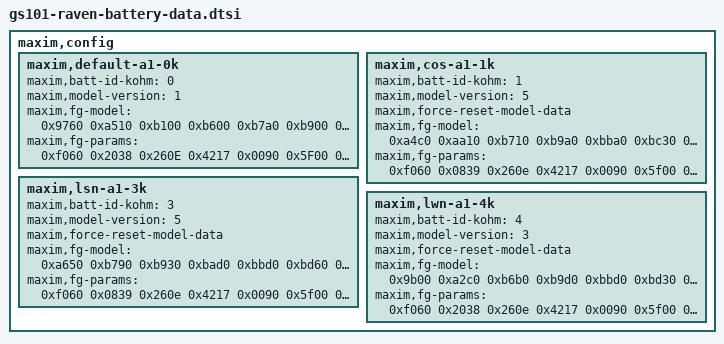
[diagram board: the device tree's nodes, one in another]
// SPDX-License-Identifier: GPL-2.0-only
/*
 * Battery device tree entries
 *
 * Copyright 2020 Google LLC
 *
 */

/* R4_p1_gen.ini, 2021-01-21, b/174787673, generic model */
maxim,config {

	/* R4_p1_gen.ini, 2021-01-21, b/174787673, generic model */
	maxim,default-a1-0k {
		maxim,batt-id-kohm = <0>;
		maxim,model-version = <1>;
		maxim,fg-model = /bits/ 16 <
			0x9760 0xa510 0xb100 0xb600 0xb7a0 0xb900 0xba70 0xbc70
			0xbde0 0xbfc0 0xc250 0xc510 0xc990 0xcea0 0xd040 0xd750
			0x0060 0x0120 0x0200 0x0710 0x0e80 0x0df0 0x1430 0x1bd0
			0x1520 0x0d70 0x0950 0x08e0 0x0800 0x0780 0x06b0 0x01e0
			0x0100 0x0100 0x0100 0x0100 0x0100 0x0100 0x0100 0x0100
			0x0100 0x0100 0x0100 0x0100 0x0100 0x0100 0x0100 0x0100
		>;
		maxim,fg-params = /bits/ 16 <
			/* 0x0036 */	0xf060	/* IAvgEmpty */
			/* 0x002a */	0x2038	/* RelaxCFG */
			/* 0x0028 */	0x260E	/* LearnCFG */
			/* 0x001D */	0x4217	/* Config */
			/* 0x00BB */	0x0090	/* Config2 */
			/* 0x0013 */	0x5F00	/* FullSOCthr */
			/* 0x0035 */	0x0994	/* FullCAPRep */
			/* 0x0018 */	0x0994	/* DesignCap */
			/* 0x0046 */	0x0c80	/* dPacc */
			/* 0x0045 */	0x0099	/* dQacc */
			/* 0x0023 */	0x0994	/* FullCAPNom */
			/* 0x003A */	0xA561	/* V_empty */
			/* 0x0012 */	0x1100	/* QResidual00 */
			/* 0x0022 */	0x0800	/* QResidual10 */
			/* 0x0032 */	0x0301	/* QResidual20 */
			/* 0x0042 */	0x0302	/* QResidual30 */
			/* 0x0038 */	0x0700	/* RCOMP0 */
			/* 0x0039 */	0x223E	/* TempCo */
			/* 0x001E */	0x0310	/* ICHGTerm */
			/* 0x002C */	0xED51	/* TGain */
			/* 0x002D */	0x1EBA	/* TOff */
			/* 0x00B9 */	0x0014	/* Curve */
			/* 0x002B */	0x3870	/* MiscCFG */
			/* 0x0004 */	0x0000	/* AtRate */
			/* 0x0049 */	0x2241	/* convgcfg */
			/* 0x0029 */	0xc623	/* FilterCFG */
			/* 0x003c */	0x2D00	/* TaskPeriod */
		>;
	};

	/* ATL: 1_ATL_2937_2_011421_3.3V_RC2_V03.txt, 2021-11-18, b/205853069 */
	maxim,cos-a1-1k {
		maxim,batt-id-kohm = <1>;
		maxim,model-version = <5>;
		maxim,force-reset-model-data;
		maxim,fg-model = /bits/ 16 <
			0xa4c0 0xaa10 0xb710 0xb9a0 0xbba0 0xbc30 0xbd20 0xbeb0
			0xc030 0xc2e0 0xc560 0xc980 0xcbf0 0xcf10 0xd600 0xdc00
			0x02f0 0x0140 0x0a50 0x0df0 0x13a0 0x0d80 0x1af0 0x1300
			0x0d10 0x07a0 0x0810 0x07c0 0x0780 0x0690 0x0730 0x0730
			0x0200 0x0200 0x0200 0x0200 0x0200 0x0200 0x0200 0x0200
			0x0200 0x0200 0x0200 0x0200 0x0200 0x0200 0x0200 0x0200
		>;
		maxim,fg-params = /bits/ 16 <
			/* 0x0036 */	0xf060	/* IAvgEmpty */
			/* 0x002a */	0x0839	/* RelaxCFG */
			/* 0x0028 */	0x260e	/* LearnCFG */
			/* 0x001D */	0x4217	/* Config */
			/* 0x00BB */	0x0090	/* Config2 */
			/* 0x0013 */	0x5f00	/* FullSOCthr */
			/* 0x0035 */	0x09d6	/* FullCAPRep */
			/* 0x0018 */	0x09d6	/* DesignCap */
			/* 0x0046 */	0x3200	/* dPacc */
			/* 0x0045 */	0x0275	/* dQacc */
			/* 0x0023 */	0x09d6	/* FullCAPNom */
			/* 0x003A */	0xa561	/* V_empty */
			/* 0x0012 */	0x3100	/* QResidual00 */
			/* 0x0022 */	0x1580	/* QResidual10 */
			/* 0x0032 */	0x0800	/* QResidual20 */
			/* 0x0042 */	0x0780	/* QResidual30 */
			/* 0x0038 */	0x0860	/* RCOMP0 */
			/* 0x0039 */	0x0d02	/* TempCo */
			/* 0x001E */	0x0620	/* ICHGTerm */
			/* 0x002C */	0xED51	/* TGain */
			/* 0x002D */	0x1EBA	/* TOff */
			/* 0x00B9 */	0x0014	/* Curve */
			/* 0x002B */	0x3870	/* MiscCFG */
			/* 0x0004 */	0x1900	/* AtRate */
			/* 0x0049 */	0x2241	/* convgcfg */
			/* 0x0029 */	0xc623	/* FilterCFG */
			/* 0x003c */	0x2D00	/* TaskPeriod */
		>;
	};

	/* LSN: 3_LSN_2992_2_040921_3.3_RC2_V03.txt, 2021-11-18, b/205853069 */
	maxim,lsn-a1-3k {
		maxim,batt-id-kohm = <3>;
		maxim,model-version = <5>;
		maxim,force-reset-model-data;
		maxim,fg-model = /bits/ 16 <
			0xa650 0xb790 0xb930 0xbad0 0xbbd0 0xbd60 0xbe80 0xc090
			0xc320 0xc590 0xc890 0xcbf0 0xcdf0 0xd5f0 0xd8b0 0xdd10
			0x01f0 0x0a00 0x0d00 0x1300 0x1350 0x17a0 0x1180 0x0ce0
			0x08c0 0x0750 0x06f0 0x0af0 0x05e0 0x08e0 0x0580 0x0580
			0x0200 0x0200 0x0200 0x0200 0x0200 0x0200 0x0200 0x0200
			0x0200 0x0200 0x0200 0x0200 0x0200 0x0200 0x0200 0x0200
		>;
		maxim,fg-params = /bits/ 16 <
			/* 0x0036 */	0xf060	/* IAvgEmpty */
			/* 0x002a */	0x0839	/* RelaxCFG */
			/* 0x0028 */	0x260e	/* LearnCFG */
			/* 0x001D */	0x4217	/* Config */
			/* 0x00BB */	0x0090	/* Config2 */
			/* 0x0013 */	0x5f00	/* FullSOCthr */
			/* 0x0035 */	0x0A2A	/* FullCAPRep */
			/* 0x0018 */	0x0A2A	/* DesignCap */
			/* 0x0046 */	0x3200	/* dPacc */
			/* 0x0045 */	0x028A	/* dQacc */
			/* 0x0023 */	0x0A2A	/* FullCAPNom */
			/* 0x003A */	0xa561	/* V_empty */
			/* 0x0012 */	0x3180	/* QResidual00 */
			/* 0x0022 */	0x1580	/* QResidual10 */
			/* 0x0032 */	0x0780	/* QResidual20 */
			/* 0x0042 */	0x0580	/* QResidual30 */
			/* 0x0038 */	0x06E0	/* RCOMP0 */
			/* 0x0039 */	0x0a02	/* TempCo */
			/* 0x001E */	0x0620	/* ICHGTerm */
			/* 0x002C */	0xED51	/* TGain */
			/* 0x002D */	0x1EBA	/* TOff */
			/* 0x00B9 */	0x0014	/* Curve */
			/* 0x002B */	0x3870	/* MiscCFG */
			/* 0x0004 */	0x1900	/* AtRate */
			/* 0x0049 */	0x2241	/* convgcfg */
			/* 0x0029 */	0xc623	/* FilterCFG */
			/* 0x003c */	0x2D00	/* TaskPeriod */
		>;
	};

	/* LWN: 4_LWN_011521_RC2, 2021-03-18, b/183051702, characterized INI */
	maxim,lwn-a1-4k {
		maxim,batt-id-kohm = <4>;
		maxim,model-version = <3>;
		maxim,force-reset-model-data;
		maxim,fg-model = /bits/ 16 <
			0x9b00 0xa2c0 0xb6b0 0xb9d0 0xbbd0 0xbd30 0xbe00 0xbf00
			0xc050 0xc280 0xc390 0xc910 0xce50 0xd150 0xd520 0xdbb0
			0x0050 0x00e0 0x0d10 0x1050 0x15b0 0x1920 0x1710 0x1260
			0x0ca0 0x07a0 0x07d0 0x0750 0x0790 0x05f0 0x06a0 0x06a0
			0x0200 0x0200 0x0200 0x0200 0x0200 0x0200 0x0200 0x0200
			0x0200 0x0200 0x0200 0x0200 0x0200 0x0200 0x0200 0x0200
		>;
		maxim,fg-params = /bits/ 16 <
			/* 0x0036 */	0xf060	/* IAvgEmpty */
			/* 0x002a */	0x2038	/* RelaxCFG */
			/* 0x0028 */	0x260e	/* LearnCFG */
			/* 0x001D */	0x4217	/* Config */
			/* 0x00BB */	0x0090	/* Config2 */
			/* 0x0013 */	0x5f00	/* FullSOCthr */
			/* 0x0035 */	0x09ee	/* FullCAPRep */
			/* 0x0018 */	0x09ee	/* DesignCap */
			/* 0x0046 */	0x0C80	/* dPacc */
			/* 0x0045 */	0x009D	/* dQacc */
			/* 0x0023 */	0x09ee	/* FullCAPNom */
			/* 0x003A */	0xA561	/* V_empty */
			/* 0x0012 */	0x1606	/* QResidual00 */
			/* 0x0022 */	0x0a00	/* QResidual10 */
			/* 0x0032 */	0x0480	/* QResidual20 */
			/* 0x0042 */	0x0400	/* QResidual30 */
			/* 0x0038 */	0x0a00	/* RCOMP0 */
			/* 0x0039 */	0x0c00	/* TempCo */
			/* 0x001E */	0x0310	/* ICHGTerm */
			/* 0x002C */	0xED51	/* TGain */
			/* 0x002D */	0x1EBA	/* TOff */
			/* 0x00B9 */	0x0014	/* Curve */
			/* 0x002B */	0x3870	/* MiscCFG */
			/* 0x0004 */	0x0000	/* AtRate */
			/* 0x0049 */	0x2241	/* convgcfg */
			/* 0x0029 */	0xc623	/* FilterCFG */
			/* 0x003c */	0x2D00	/* TaskPeriod */
		>;
	};

};
